# Qorvo_SVD register map
Vendor: Qorvo Inc; Series: ARMCM4; File version: 1.0
Registers are 8-bit, read-write, reset 0x0 unless marked. A register's access mark holds for its fields unless they carry their own. Offsets are from the block's base; [hi:lo] are bit positions; {n}, {i} and the like mark numbered series.

## WATCHDOG
Base 0x40001120
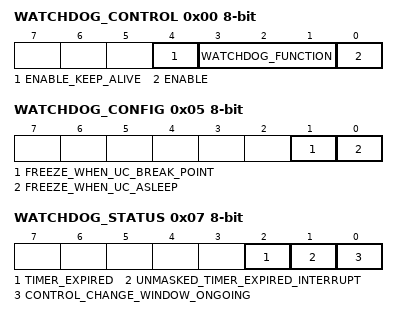
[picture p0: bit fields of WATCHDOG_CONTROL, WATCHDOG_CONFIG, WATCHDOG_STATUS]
0x00 WATCHDOG_CONTROL
  [4] ENABLE_KEEP_ALIVE — When set to 1 a keep alive mechanism is enabled, where the standby RC clock is used to check if the main clock is still runninig. A POR will be triggered if the main clock is not running
  [3:1] WATCHDOG_FUNCTION — Function of watchdog, triggered when timer reaches zero - Writing this register only has effect when in the control settings change sequence
  [0] ENABLE — Watchdog enabled when 0x1 - Writing this register only has effect when in the control settings change sequence
0x02 WATCHDOG_TIMEOUT 16-bit reset 0xFFFF
  [15:0] TIMEOUT — Watchdog timeout value in 16 us - Writing this register only has effect when in the control settings change sequence
0x05 WATCHDOG_CONFIG
  [1] FREEZE_WHEN_UC_BREAK_POINT — When set to 1, the watchdog timer will be frozen whan the internal uc hits a break point in debug mode
  [0] FREEZE_WHEN_UC_ASLEEP — When set to 1, the watchdog timer will be frozen whan the internal uc goes to sleep
0x07 WATCHDOG_STATUS ro
  [2] TIMER_EXPIRED — Indicates that the timer has reached 0. This status is reset by a watchdog reset, or by a control settings change
  [1] UNMASKED_TIMER_EXPIRED_INTERRUPT — Unmasked status of the timer expired interrupt
  [0] CONTROL_CHANGE_WINDOW_ONGOING — This status bit indicates that the window for changing watchdog control settings is open. Control settings can only be changed when this status bit is 1
0x08 WATCHDOG_CURRENT_TIME 16-bit ro
  [15:0] CURRENT_TIME — Watchdog current time (16 us multiples)

## LEDS
Base 0x40001140
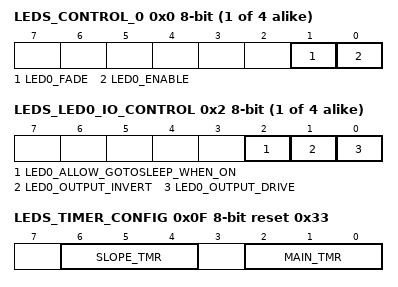
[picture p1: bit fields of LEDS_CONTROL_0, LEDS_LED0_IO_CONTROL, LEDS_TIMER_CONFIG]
{0x0+4i} LEDS_CONTROL_{i} (i=0..3)
  [1] LED{i}_FADE — When set to 1, fading will be used when enabling or disabling the led
  [0] LED{i}_ENABLE — Set to 1 to enable the led
0x01 LEDS_0X00000001 reset 0xFF
  [7:0] LED0_THRESHOLD — Sets the target PWM threshold (255 = max duty cycle)
{0x2+4i} LEDS_LED{i}_IO_CONTROL (i=0..3)
  [2] LED{i}_ALLOW_GOTOSLEEP_WHEN_ON — When set, the chip may go to sleep, even if the led is driven continuously (dutycycling prevents chip from going to sleep)
  [1] LED{i}_OUTPUT_INVERT — Inverts the output
  [0] LED{i}_OUTPUT_DRIVE — Sets the drive type for the output
0x05 LEDS_0X00000005 reset 0xFF
  [7:0] LED1_THRESHOLD — Sets the target PWM threshold (255 = max duty cycle)
0x09 LEDS_0X00000009 reset 0xFF
  [7:0] LED2_THRESHOLD — Sets the target PWM threshold (255 = max duty cycle)
0x0D LEDS_0X0000000D reset 0xFF
  [7:0] LED3_THRESHOLD — Sets the target PWM threshold (255 = max duty cycle)
0x0F LEDS_TIMER_CONFIG reset 0x33
  [6:4] SLOPE_TMR — Sets the timer to use for updating the threshold, each slope timer wrap shall increment/decrement the threshold (if fading is enabled)
  [2:0] MAIN_TMR — Sets the timer to use for the main counter, which gets compared to the thresholds
0x10 LEDS_0X00000010 ro
  [0] DUMMY_STATUS — dummy - regmap generation thing ...

## SPI_SL
Base 0x400011C0
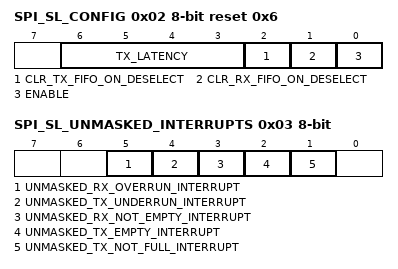
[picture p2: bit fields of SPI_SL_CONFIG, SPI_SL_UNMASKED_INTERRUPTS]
0x02 SPI_SL_CONFIG reset 0x6
  [6:3] TX_LATENCY — Amount of dummy of bytes that shift out of the MISO after the slave is selected and before real data is transmitted. Number of dummy bytes = tx_latency + 1
  [2] CLR_TX_FIFO_ON_DESELECT — When set, the tx data byte buffer will be cleared whn the ssn pin is inactive
  [1] CLR_RX_FIFO_ON_DESELECT — When set, the rx data byte buffer will be cleared whn the ssn pin is inactive
  [0] ENABLE — Enable core when '1'
0x03 SPI_SL_UNMASKED_INTERRUPTS ro
  [5] UNMASKED_RX_OVERRUN_INTERRUPT — Status and unmasked interrupt flag for the occurrence of a rx data buffer overrun. Set when the rx data buffer is full and new rx data is available. Cleared explicitly by the SW.
  [4] UNMASKED_TX_UNDERRUN_INTERRUPT — Status and unmasked interrupt flag for the occurrence of a tx data buffer underrun. Set when the tx data buffer is empty when master pulls data from slave. Cleared explicitly by the SW.
  [3] UNMASKED_RX_NOT_EMPTY_INTERRUPT — Status and unmasked interrupt flag for RX buffer not empty. The interrupt is cleared implicitly when reading the last RX data from the buffer.
  [2] UNMASKED_TX_EMPTY_INTERRUPT — Status and unmasked interrupt flag for TX bufferbeing empty. The interrupt is cleared implicitly when writing new TX data fills the buffer.
  [1] UNMASKED_TX_NOT_FULL_INTERRUPT — Status and unmasked interrupt flag for TX buffer not full. The interrupt is cleared implicitly when writing new TX data fills the buffer.
